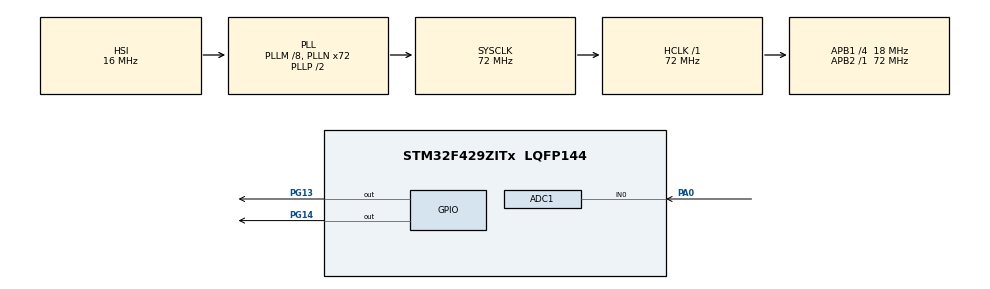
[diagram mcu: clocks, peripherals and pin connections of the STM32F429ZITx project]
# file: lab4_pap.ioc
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ADC1.Channel-0\#ChannelRegularConversion=ADC_CHANNEL_0
ADC1.NbrOfConversionFlag=1
ADC1.Rank-0\#ChannelRegularConversion=1
ADC1.SamplingTime-0\#ChannelRegularConversion=ADC_SAMPLETIME_3CYCLES
ADC1.master=1
Mcu.Family=STM32F4
Mcu.Name=STM32F429ZITx
Mcu.Package=LQFP144
NVIC.ADC_IRQn=true\:0\:0\:false\:true\:true\:1\:true\:true\:true
NVIC.PriorityGroup=NVIC_PRIORITYGROUP_4
NVIC.TIM2_IRQn=true\:0\:0\:false\:true\:true\:2\:true\:true\:true
PA0/WKUP.Signal=ADCx_IN0
PG13.Signal=GPIO_Output
PG14.Signal=GPIO_Output
ProjectManager.HeapSize=0x200
ProjectManager.StackSize=0x400
ProjectManager.TargetToolchain=STM32CubeIDE
RCC.48MHZClocksFreq_Value=48000000
RCC.AHBFreq_Value=72000000
RCC.APB1CLKDivider=RCC_HCLK_DIV4
RCC.APB1Freq_Value=18000000
RCC.APB1TimFreq_Value=36000000
RCC.APB2Freq_Value=72000000
RCC.APB2TimFreq_Value=72000000
RCC.CortexFreq_Value=72000000
RCC.HCLKFreq_Value=72000000
RCC.HSE_VALUE=8000000
RCC.HSI_VALUE=16000000
RCC.LSE_VALUE=32768
RCC.PLLM=8
RCC.PLLN=72
RCC.PLLQ=3
RCC.PLLSAIN=50
RCC.SYSCLKFreq_VALUE=72000000
RCC.SYSCLKSource=RCC_SYSCLKSOURCE_PLLCLK
RCC.VCOOutputFreq_Value=144000000
SH.ADCx_IN0.0=ADC1_IN0,IN0
TIM2.Period=1000
TIM2.Prescaler=3600
VP_TIM2_VS_ClockSourceINT.Mode=Internal
board=STM32F429I-DISC1

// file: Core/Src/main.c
/* USER CODE BEGIN Header */
/**
  ******************************************************************************
  * @file           : main.c
  * @brief          : Main program body
  ******************************************************************************
  * @attention
  *
  * Copyright (c) 2026 STMicroelectronics.
  * All rights reserved.
  *
  * This software is licensed under terms that can be found in the LICENSE file
  * in the root directory of this software component.
  * If no LICENSE file comes with this software, it is provided AS-IS.
  *
  ******************************************************************************
  */
/* USER CODE END Header */
#include "main.h"

ADC_HandleTypeDef hadc1;

TIM_HandleTypeDef htim2;

/* USER CODE BEGIN PV */
int task = 1;

volatile uint32_t adc_val = 0;

/* USER CODE END PV */

void SystemClock_Config(void);
static void MX_GPIO_Init(void);
static void MX_ADC1_Init(void);
static void MX_TIM2_Init(void);
static void MX_NVIC_Init(void);

int main(void)
{

  /* MCU Configuration--------------------------------------------------------*/

  /* Reset of all peripherals, Initializes the Flash interface and the Systick. */
  HAL_Init();

  /* Configure the system clock */
  SystemClock_Config();

  /* Initialize all configured peripherals */
  MX_GPIO_Init();
  MX_ADC1_Init();
  MX_TIM2_Init();

  /* Initialize interrupts */
  MX_NVIC_Init();
  /* USER CODE BEGIN 2 */
  HAL_TIM_Base_Start_IT(&htim2);
  /* USER CODE END 2 */

  /* Infinite loop */
  while (1)
  {

  }
}

void SystemClock_Config(void)
{
  RCC_OscInitTypeDef RCC_OscInitStruct = {0};
  RCC_ClkInitTypeDef RCC_ClkInitStruct = {0};

  /** Configure the main internal regulator output voltage
  */
  __HAL_RCC_PWR_CLK_ENABLE();
  __HAL_PWR_VOLTAGESCALING_CONFIG(PWR_REGULATOR_VOLTAGE_SCALE3);

  /** Initializes the RCC Oscillators according to the specified parameters
  * in the RCC_OscInitTypeDef structure.
  */
  RCC_OscInitStruct.OscillatorType = RCC_OSCILLATORTYPE_HSI;
  RCC_OscInitStruct.HSIState = RCC_HSI_ON;
  RCC_OscInitStruct.HSICalibrationValue = RCC_HSICALIBRATION_DEFAULT;
  RCC_OscInitStruct.PLL.PLLState = RCC_PLL_ON;
  RCC_OscInitStruct.PLL.PLLSource = RCC_PLLSOURCE_HSI;
  RCC_OscInitStruct.PLL.PLLM = 8;
  RCC_OscInitStruct.PLL.PLLN = 72;
  RCC_OscInitStruct.PLL.PLLP = RCC_PLLP_DIV2;
  RCC_OscInitStruct.PLL.PLLQ = 3;
  if (HAL_RCC_OscConfig(&RCC_OscInitStruct) != HAL_OK)
  {
    Error_Handler();
  }

  /** Initializes the CPU, AHB and APB buses clocks
  */
  RCC_ClkInitStruct.ClockType = RCC_CLOCKTYPE_HCLK|RCC_CLOCKTYPE_SYSCLK
                              |RCC_CLOCKTYPE_PCLK1|RCC_CLOCKTYPE_PCLK2;
  RCC_ClkInitStruct.SYSCLKSource = RCC_SYSCLKSOURCE_PLLCLK;
  RCC_ClkInitStruct.AHBCLKDivider = RCC_SYSCLK_DIV1;
  RCC_ClkInitStruct.APB1CLKDivider = RCC_HCLK_DIV4;
  RCC_ClkInitStruct.APB2CLKDivider = RCC_HCLK_DIV1;

  if (HAL_RCC_ClockConfig(&RCC_ClkInitStruct, FLASH_LATENCY_2) != HAL_OK)
  {
    Error_Handler();
  }
}

/**
  * @brief NVIC Configuration.
  * @retval None
  */
static void MX_NVIC_Init(void)
{
  /* ADC_IRQn interrupt configuration */
  HAL_NVIC_SetPriority(ADC_IRQn, 0, 0);
  HAL_NVIC_EnableIRQ(ADC_IRQn);
  /* TIM2_IRQn interrupt configuration */
  HAL_NVIC_SetPriority(TIM2_IRQn, 0, 0);
  HAL_NVIC_EnableIRQ(TIM2_IRQn);
}

static void MX_ADC1_Init(void)
{

  ADC_ChannelConfTypeDef sConfig = {0};

  /** Configure the global features of the ADC (Clock, Resolution, Data Alignment and number of conversion)
  */
  hadc1.Instance = ADC1;
  hadc1.Init.ClockPrescaler = ADC_CLOCK_SYNC_PCLK_DIV2;
  hadc1.Init.Resolution = ADC_RESOLUTION_12B;
  hadc1.Init.ScanConvMode = DISABLE;
  hadc1.Init.ContinuousConvMode = DISABLE;
  hadc1.Init.DiscontinuousConvMode = DISABLE;
  hadc1.Init.ExternalTrigConvEdge = ADC_EXTERNALTRIGCONVEDGE_NONE;
  hadc1.Init.ExternalTrigConv = ADC_SOFTWARE_START;
  hadc1.Init.DataAlign = ADC_DATAALIGN_RIGHT;
  hadc1.Init.NbrOfConversion = 1;
  hadc1.Init.DMAContinuousRequests = DISABLE;
  hadc1.Init.EOCSelection = ADC_EOC_SINGLE_CONV;
  if (HAL_ADC_Init(&hadc1) != HAL_OK)
  {
    Error_Handler();
  }

  /** Configure for the selected ADC regular channel its corresponding rank in the sequencer and its sample time.
  */
  sConfig.Channel = ADC_CHANNEL_0;
  sConfig.Rank = 1;
  sConfig.SamplingTime = ADC_SAMPLETIME_3CYCLES;
  if (HAL_ADC_ConfigChannel(&hadc1, &sConfig) != HAL_OK)
  {
    Error_Handler();
  }

}

static void MX_TIM2_Init(void)
{

  TIM_ClockConfigTypeDef sClockSourceConfig = {0};
  TIM_MasterConfigTypeDef sMasterConfig = {0};

  htim2.Instance = TIM2;
  htim2.Init.Prescaler = 3600;
  htim2.Init.CounterMode = TIM_COUNTERMODE_UP;
  htim2.Init.Period = 1000;
  htim2.Init.ClockDivision = TIM_CLOCKDIVISION_DIV1;
  htim2.Init.AutoReloadPreload = TIM_AUTORELOAD_PRELOAD_DISABLE;
  if (HAL_TIM_Base_Init(&htim2) != HAL_OK)
  {
    Error_Handler();
  }
  sClockSourceConfig.ClockSource = TIM_CLOCKSOURCE_INTERNAL;
  if (HAL_TIM_ConfigClockSource(&htim2, &sClockSourceConfig) != HAL_OK)
  {
    Error_Handler();
  }
  sMasterConfig.MasterOutputTrigger = TIM_TRGO_RESET;
  sMasterConfig.MasterSlaveMode = TIM_MASTERSLAVEMODE_DISABLE;
  if (HAL_TIMEx_MasterConfigSynchronization(&htim2, &sMasterConfig) != HAL_OK)
  {
    Error_Handler();
  }

}

static void MX_GPIO_Init(void)
{
  GPIO_InitTypeDef GPIO_InitStruct = {0};

  /* GPIO Ports Clock Enable */
  __HAL_RCC_GPIOA_CLK_ENABLE();
  __HAL_RCC_GPIOG_CLK_ENABLE();

  /*Configure GPIO pin Output Level */
  HAL_GPIO_WritePin(GPIOG, GPIO_PIN_13|GPIO_PIN_14, GPIO_PIN_RESET);

  /*Configure GPIO pins : PG13 PG14 */
  GPIO_InitStruct.Pin = GPIO_PIN_13|GPIO_PIN_14;
  GPIO_InitStruct.Mode = GPIO_MODE_OUTPUT_PP;
  GPIO_InitStruct.Pull = GPIO_NOPULL;
  GPIO_InitStruct.Speed = GPIO_SPEED_FREQ_LOW;
  HAL_GPIO_Init(GPIOG, &GPIO_InitStruct);

}

/* USER CODE BEGIN 4 */

// 1. Ši funkcija suveikia kas 1 sekundę (TIM2_IRQHandler -> Callback)
void HAL_TIM_PeriodElapsedCallback(TIM_HandleTypeDef *htim) {
    if (htim->Instance == TIM2) {
        // Programiškai pradedame ADC konversiją su pertrauktimi
        HAL_ADC_Start_IT(&hadc1);
    }
}

// 2. Ši funkcija suveikia, kai ADC baigia matuoti įtampą (ADC_IRQHandler -> Callback)
void HAL_ADC_ConvCpltCallback(ADC_HandleTypeDef* hadc) {
	 if (hadc->Instance == ADC1)
	    {
	        adc_val = HAL_ADC_GetValue(hadc);

	        if (adc_val < 2000)
	        {
	            // LOW → tik žalias
	            HAL_GPIO_WritePin(GPIOG, GPIO_PIN_13, GPIO_PIN_SET);   // Green ON
	            HAL_GPIO_WritePin(GPIOG, GPIO_PIN_14, GPIO_PIN_RESET); // Red OFF
	        }
	        else
	        {
	            // HIGH → žalias + raudonas
	            HAL_GPIO_WritePin(GPIOG, GPIO_PIN_13, GPIO_PIN_SET);   // Green ON
	            HAL_GPIO_WritePin(GPIOG, GPIO_PIN_14, GPIO_PIN_SET);   // Red ON
	        }
	    }
}

/* USER CODE END 4 */

void Error_Handler(void)
{
  __disable_irq();
  while (1)
  {
  }
}
